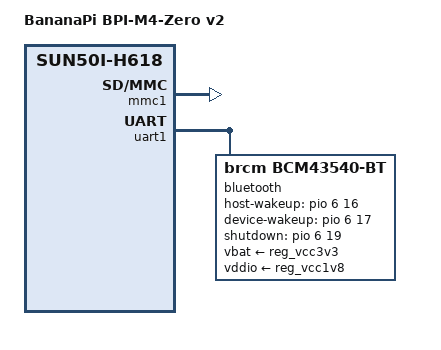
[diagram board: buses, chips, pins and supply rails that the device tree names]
/dts-v1/;
/plugin/;

#include <dt-bindings/gpio/gpio.h>

/ {
	compatible = "sinovoip,bpi-m4-zero", "allwinner,sun50i-h616", "allwinner,sun50i-h618";

	fragment@0 {
		target-path = "/";
		__overlay__ {
			model = "BananaPi BPI-M4-Zero v2";
		};
	};

	/* SDIO WIFI */
	fragment@1 {
		target = <&mmc1>;
		__overlay__ {
			status = "okay";
		};
	};

	/* BLUETOOTH */
	fragment@2 {
		target = <&uart1>;
		__overlay__ {
			status = "okay";
			pinctrl-0 = <&uart1_pins>, <&uart1_rts_cts_pins>;
			pinctrl-names = "default";
			uart-has-rtscts;

			bluetooth {
				compatible = "brcm,bcm43540-bt";
				host-wakeup-gpios = <&pio 6 16 GPIO_ACTIVE_HIGH>;
				device-wakeup-gpios = <&pio 6 17 GPIO_ACTIVE_HIGH>;
				shutdown-gpios = <&pio 6 19 GPIO_ACTIVE_HIGH>;
				max-speed = <1500000>;
				vbat-supply = <&reg_vcc3v3>;
				vddio-supply = <&reg_vcc1v8>;
			};
		};
	};
};
